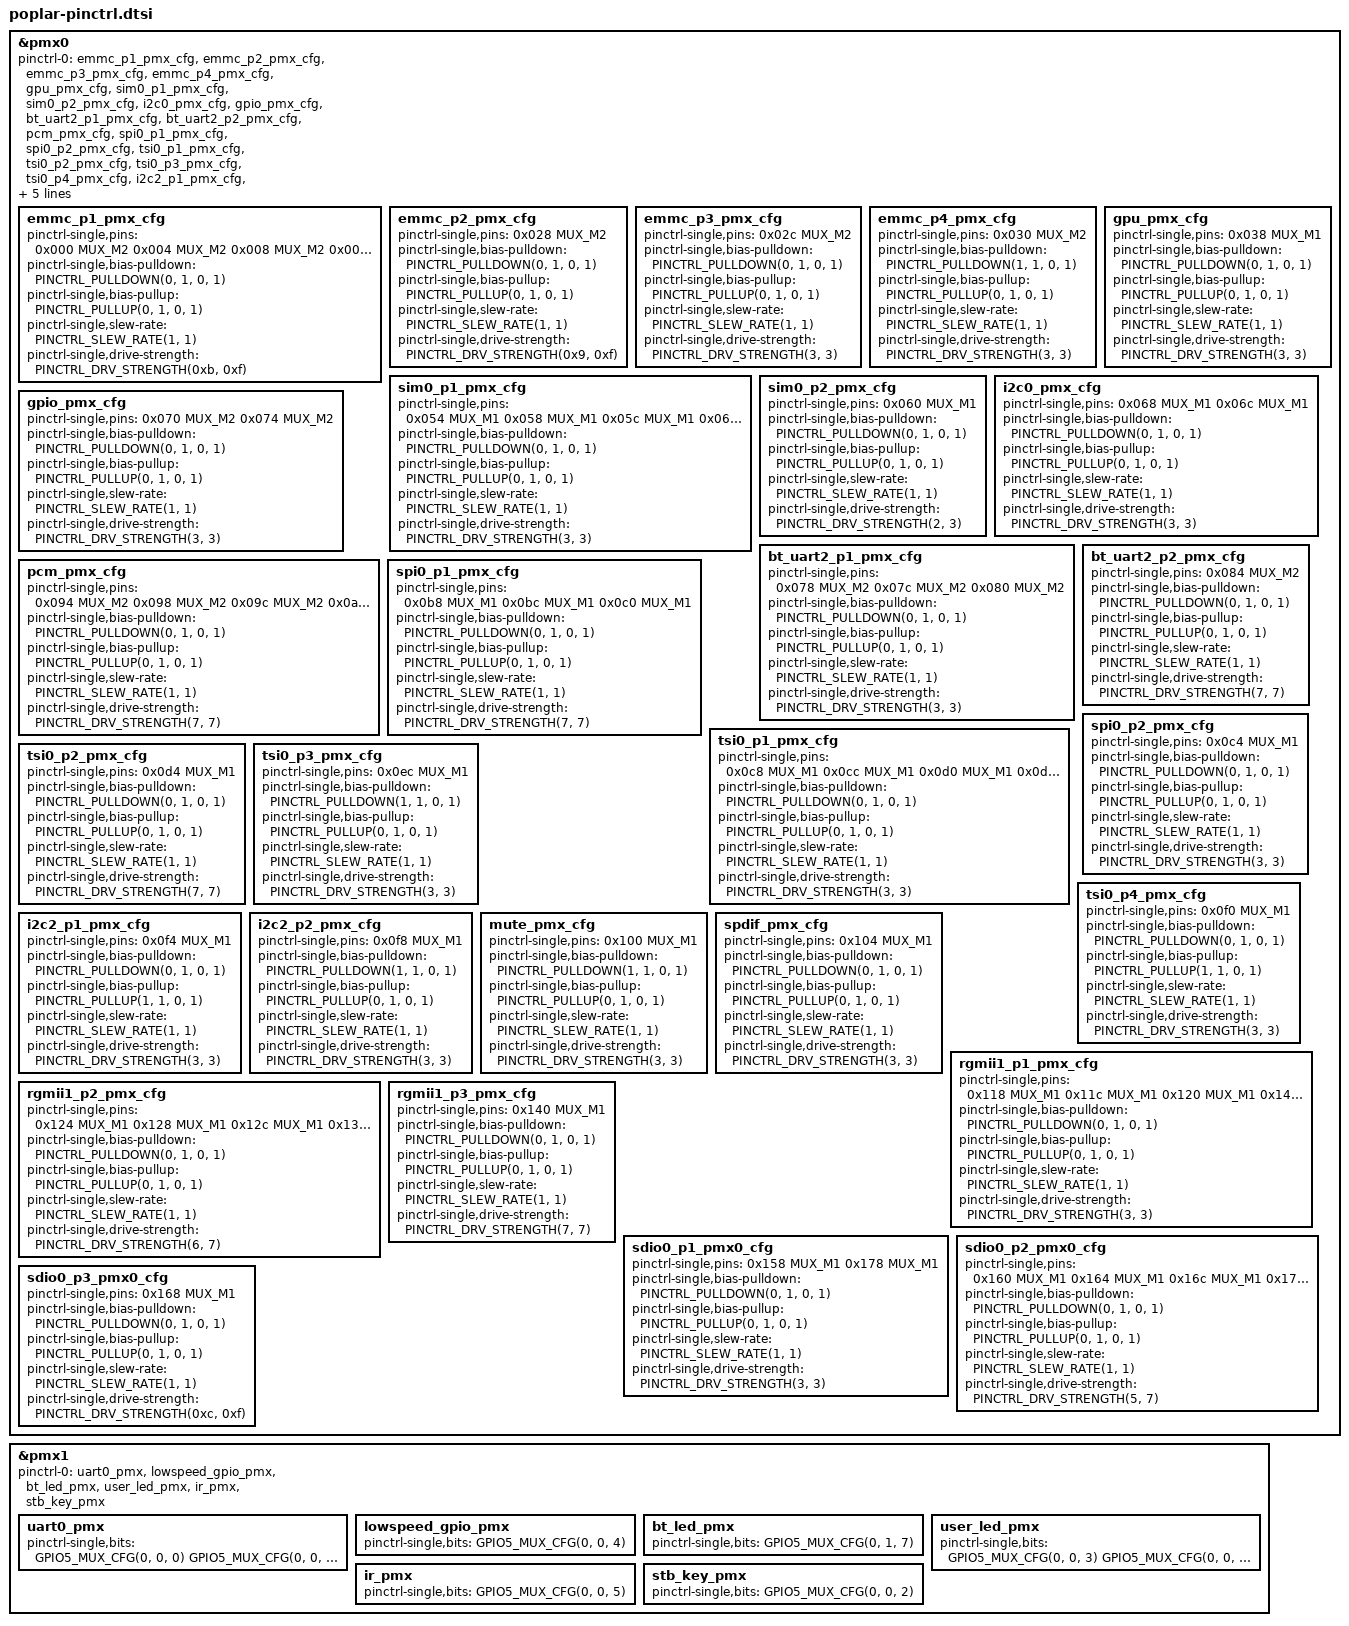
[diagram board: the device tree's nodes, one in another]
/*
 * pinctrl dts file for HiSilicon poplar board
 *
 * Copyright (c) 2016-2017 HiSilicon Technologies Co., Ltd.
 *
 * Released under the GPLv2 only.
 * SPDX-License-Identifier: GPL-2.0
 */

#include <dt-bindings/pinctrl/hisi.h>

/* value, enable bits, disable bits, mask */
#define PINCTRL_PULLDOWN(value, enable, disable, mask) \
	(value << 13) (enable << 13) (disable << 13) (mask << 13)
#define PINCTRL_PULLUP(value, enable, disable, mask) \
	(value << 12) (enable << 12) (disable << 12) (mask << 12)
#define PINCTRL_SLEW_RATE(value, mask)	  (value << 8) (mask << 8)
#define PINCTRL_DRV_STRENGTH(value, mask) (value << 4) (mask << 4)
#define GPIO5_MUX_CFG(offset, value, bit) (offset) (value << bit) (1 << bit)

&pmx0 {
	pinctrl-names = "default";
		pinctrl-0 = <
			&emmc_p1_pmx_cfg
			&emmc_p2_pmx_cfg
			&emmc_p3_pmx_cfg
			&emmc_p4_pmx_cfg
			&gpu_pmx_cfg
			&sim0_p1_pmx_cfg
			&sim0_p2_pmx_cfg
			&i2c0_pmx_cfg
			&gpio_pmx_cfg
			&bt_uart2_p1_pmx_cfg
			&bt_uart2_p2_pmx_cfg
			&pcm_pmx_cfg
			&spi0_p1_pmx_cfg
			&spi0_p2_pmx_cfg
			&tsi0_p1_pmx_cfg
			&tsi0_p2_pmx_cfg
			&tsi0_p3_pmx_cfg
			&tsi0_p4_pmx_cfg
			&i2c2_p1_pmx_cfg
			&i2c2_p2_pmx_cfg
			&mute_pmx_cfg
			&spdif_pmx_cfg
			&rgmii1_p1_pmx_cfg
			&rgmii1_p2_pmx_cfg
			&rgmii1_p3_pmx_cfg
			&sdio0_p1_pmx0_cfg
			&sdio0_p2_pmx0_cfg
			&sdio0_p3_pmx0_cfg
		>;

	emmc_p1_pmx_cfg: emmc_p1_pmx_cfg {
		pinctrl-single,pins = <
			0x000 MUX_M2
			0x004 MUX_M2
			0x008 MUX_M2
			0x00c MUX_M2
			0x010 MUX_M2
			0x014 MUX_M2
			0x018 MUX_M2
			0x01c MUX_M2
			0x024 MUX_M2
		>;
		pinctrl-single,bias-pulldown	= <
			PINCTRL_PULLDOWN(0, 1, 0, 1)
		>;
		pinctrl-single,bias-pullup	= <
			PINCTRL_PULLUP(0, 1, 0, 1)
		>;
		pinctrl-single,slew-rate	= <
			PINCTRL_SLEW_RATE(1, 1)
		>;
		pinctrl-single,drive-strength	= <
			PINCTRL_DRV_STRENGTH(0xb, 0xf)
		>;
	};

	emmc_p2_pmx_cfg: emmc_p2_pmx_cfg {
		pinctrl-single,pins = <
			0x028 MUX_M2
		>;
		pinctrl-single,bias-pulldown	= <
			PINCTRL_PULLDOWN(0, 1, 0, 1)
		>;
		pinctrl-single,bias-pullup	= <
			PINCTRL_PULLUP(0, 1, 0, 1)
		>;
		pinctrl-single,slew-rate	= <
			PINCTRL_SLEW_RATE(1, 1)
		>;
		pinctrl-single,drive-strength	= <
			PINCTRL_DRV_STRENGTH(0x9, 0xf)
		>;
	};

	emmc_p3_pmx_cfg:emmc_p3_pmx_cfg {
		pinctrl-single,pins = <
			0x02c MUX_M2
		>;
		pinctrl-single,bias-pulldown	= <
			PINCTRL_PULLDOWN(0, 1, 0, 1)
		>;
		pinctrl-single,bias-pullup	= <
			PINCTRL_PULLUP(0, 1, 0, 1)
		>;
		pinctrl-single,slew-rate	= <
			PINCTRL_SLEW_RATE(1, 1)
		>;
		pinctrl-single,drive-strength	= <
			PINCTRL_DRV_STRENGTH(3, 3)
		>;
	};

	emmc_p4_pmx_cfg:emmc_p4_pmx_cfg {
		pinctrl-single,pins = <
			0x030 MUX_M2
		>;
		pinctrl-single,bias-pulldown	= <
			PINCTRL_PULLDOWN(1, 1, 0, 1)
		>;
		pinctrl-single,bias-pullup	= <
			PINCTRL_PULLUP(0, 1, 0, 1)
		>;
		pinctrl-single,slew-rate	= <
			PINCTRL_SLEW_RATE(1, 1)
		>;
		pinctrl-single,drive-strength	= <
			PINCTRL_DRV_STRENGTH(3, 3)
		>;
	};

	gpu_pmx_cfg: gpu_pmx_cfg {
		pinctrl-single,pins = <
			0x038 MUX_M1
		>;
		pinctrl-single,bias-pulldown	= <
			PINCTRL_PULLDOWN(0, 1, 0, 1)
		>;
		pinctrl-single,bias-pullup	= <
			PINCTRL_PULLUP(0, 1, 0, 1)
		>;
		pinctrl-single,slew-rate	= <
			PINCTRL_SLEW_RATE(1, 1)
		>;
		pinctrl-single,drive-strength	= <
			PINCTRL_DRV_STRENGTH(3, 3)
		>;
	};

	sim0_p1_pmx_cfg: sim0_p1_pmx_cfg {
		pinctrl-single,pins = <
			0x054 MUX_M1
			0x058 MUX_M1
			0x05c MUX_M1
			0x064 MUX_M1
		>;
		pinctrl-single,bias-pulldown	= <
			PINCTRL_PULLDOWN(0, 1, 0, 1)
		>;
		pinctrl-single,bias-pullup	= <
			PINCTRL_PULLUP(0, 1, 0, 1)
		>;
		pinctrl-single,slew-rate	= <
			PINCTRL_SLEW_RATE(1, 1)
		>;
		pinctrl-single,drive-strength	= <
			PINCTRL_DRV_STRENGTH(3, 3)
		>;
	};

	sim0_p2_pmx_cfg: sim0_p2_pmx_cfg {
		pinctrl-single,pins = <
			0x060 MUX_M1
		>;
		pinctrl-single,bias-pulldown	= <
			PINCTRL_PULLDOWN(0, 1, 0, 1)
		>;
		pinctrl-single,bias-pullup	= <
			PINCTRL_PULLUP(0, 1, 0, 1)
		>;
		pinctrl-single,slew-rate	= <
			PINCTRL_SLEW_RATE(1, 1)
		>;
		pinctrl-single,drive-strength	= <
			PINCTRL_DRV_STRENGTH(2, 3)
		>;
	};

	i2c0_pmx_cfg: i2c0_pmx_cfg {
		pinctrl-single,pins = <
			0x068 MUX_M1
			0x06c MUX_M1
		>;
		pinctrl-single,bias-pulldown	= <
			PINCTRL_PULLDOWN(0, 1, 0, 1)
		>;
		pinctrl-single,bias-pullup	= <
			PINCTRL_PULLUP(0, 1, 0, 1)
		>;
		pinctrl-single,slew-rate	= <
			PINCTRL_SLEW_RATE(1, 1)
		>;
		pinctrl-single,drive-strength	= <
			PINCTRL_DRV_STRENGTH(3, 3)
		>;
	};

	gpio_pmx_cfg: gpio_pmx_cfg {
		pinctrl-single,pins = <
			0x070 MUX_M2
			0x074 MUX_M2
		>;
		pinctrl-single,bias-pulldown	= <
			PINCTRL_PULLDOWN(0, 1, 0, 1)
		>;
		pinctrl-single,bias-pullup	= <
			PINCTRL_PULLUP(0, 1, 0, 1)
		>;
		pinctrl-single,slew-rate	= <
			PINCTRL_SLEW_RATE(1, 1)
		>;
		pinctrl-single,drive-strength	= <
			PINCTRL_DRV_STRENGTH(3, 3)
		>;
	};

	bt_uart2_p1_pmx_cfg: bt_uart2_p1_pmx_cfg {
		pinctrl-single,pins = <
			0x078 MUX_M2
			0x07c MUX_M2
			0x080 MUX_M2
		>;
		pinctrl-single,bias-pulldown	= <
			PINCTRL_PULLDOWN(0, 1, 0, 1)
		>;
		pinctrl-single,bias-pullup	= <
			PINCTRL_PULLUP(0, 1, 0, 1)
		>;
		pinctrl-single,slew-rate	= <
			PINCTRL_SLEW_RATE(1, 1)
		>;
		pinctrl-single,drive-strength	= <
			PINCTRL_DRV_STRENGTH(3, 3)
		>;
	};

	bt_uart2_p2_pmx_cfg: bt_uart2_p2_pmx_cfg {
		pinctrl-single,pins = <
			0x084 MUX_M2
		>;
		pinctrl-single,bias-pulldown	= <
			PINCTRL_PULLDOWN(0, 1, 0, 1)
		>;
		pinctrl-single,bias-pullup	= <
			PINCTRL_PULLUP(0, 1, 0, 1)
		>;
		pinctrl-single,slew-rate	= <
			PINCTRL_SLEW_RATE(1, 1)
		>;
		pinctrl-single,drive-strength	= <
			PINCTRL_DRV_STRENGTH(7, 7)
		>;
	};

	pcm_pmx_cfg: pcm_pmx_cfg {
		pinctrl-single,pins = <
			0x094 MUX_M2
			0x098 MUX_M2
			0x09c MUX_M2
			0x0a0 MUX_M2
		>;
		pinctrl-single,bias-pulldown	= <
			PINCTRL_PULLDOWN(0, 1, 0, 1)
		>;
		pinctrl-single,bias-pullup	= <
			PINCTRL_PULLUP(0, 1, 0, 1)
		>;
		pinctrl-single,slew-rate	= <
			PINCTRL_SLEW_RATE(1, 1)
		>;
		pinctrl-single,drive-strength	= <
			PINCTRL_DRV_STRENGTH(7, 7)
		>;
	};

	spi0_p1_pmx_cfg: spi0_p1_pmx_cfg {
		pinctrl-single,pins = <
			0x0b8 MUX_M1
			0x0bc MUX_M1
			0x0c0 MUX_M1
		>;
		pinctrl-single,bias-pulldown	= <
			PINCTRL_PULLDOWN(0, 1, 0, 1)
		>;
		pinctrl-single,bias-pullup	= <
			PINCTRL_PULLUP(0, 1, 0, 1)
		>;
		pinctrl-single,slew-rate	= <
			PINCTRL_SLEW_RATE(1, 1)
		>;
		pinctrl-single,drive-strength	= <
			PINCTRL_DRV_STRENGTH(7, 7)
		>;
	};

	spi0_p2_pmx_cfg: spi0_p2_pmx_cfg {
		pinctrl-single,pins = <
			0x0c4 MUX_M1
		>;
		pinctrl-single,bias-pulldown	= <
			PINCTRL_PULLDOWN(0, 1, 0, 1)
		>;
		pinctrl-single,bias-pullup	= <
			PINCTRL_PULLUP(0, 1, 0, 1)
		>;
		pinctrl-single,slew-rate	= <
			PINCTRL_SLEW_RATE(1, 1)
		>;
		pinctrl-single,drive-strength	= <
			PINCTRL_DRV_STRENGTH(3, 3)
		>;
	};

	tsi0_p1_pmx_cfg: tsi0_p1_pmx_cfg {
		pinctrl-single,pins = <
			0x0c8 MUX_M1
			0x0cc MUX_M1
			0x0d0 MUX_M1
			0x0d8 MUX_M1
			0x0dc MUX_M1
			0x0e0 MUX_M1
			0x0e4 MUX_M1
			0x0e8 MUX_M1
		>;
		pinctrl-single,bias-pulldown	= <
			PINCTRL_PULLDOWN(0, 1, 0, 1)
		>;
		pinctrl-single,bias-pullup	= <
			PINCTRL_PULLUP(0, 1, 0, 1)
		>;
		pinctrl-single,slew-rate	= <
			PINCTRL_SLEW_RATE(1, 1)
		>;
		pinctrl-single,drive-strength	= <
			PINCTRL_DRV_STRENGTH(3, 3)
		>;
	};

	tsi0_p2_pmx_cfg: tsi0_p2_pmx_cfg {
		pinctrl-single,pins = <
			0x0d4 MUX_M1
		>;
		pinctrl-single,bias-pulldown	= <
			PINCTRL_PULLDOWN(0, 1, 0, 1)
		>;
		pinctrl-single,bias-pullup	= <
			PINCTRL_PULLUP(0, 1, 0, 1)
		>;
		pinctrl-single,slew-rate	= <
			PINCTRL_SLEW_RATE(1, 1)
		>;
		pinctrl-single,drive-strength	= <
			PINCTRL_DRV_STRENGTH(7, 7)
		>;
	};

	tsi0_p3_pmx_cfg: tsi0_p3_pmx_cfg {
		pinctrl-single,pins = <
			0x0ec MUX_M1
		>;
		pinctrl-single,bias-pulldown	= <
			PINCTRL_PULLDOWN(1, 1, 0, 1)
		>;
		pinctrl-single,bias-pullup	= <
			PINCTRL_PULLUP(0, 1, 0, 1)
		>;
		pinctrl-single,slew-rate	= <
			PINCTRL_SLEW_RATE(1, 1)
		>;
		pinctrl-single,drive-strength	= <
			PINCTRL_DRV_STRENGTH(3, 3)
		>;
	};

	tsi0_p4_pmx_cfg: tsi0_p4_pmx_cfg  {
		pinctrl-single,pins = <
			0x0f0 MUX_M1
		>;
		pinctrl-single,bias-pulldown	= <
			PINCTRL_PULLDOWN(0, 1, 0, 1)
		>;
		pinctrl-single,bias-pullup	= <
			PINCTRL_PULLUP(1, 1, 0, 1)
		>;
		pinctrl-single,slew-rate	= <
			PINCTRL_SLEW_RATE(1, 1)
		>;
		pinctrl-single,drive-strength	= <
			PINCTRL_DRV_STRENGTH(3, 3)
		>;
	};

	i2c2_p1_pmx_cfg: i2c2_p1_pmx_cfg {
		pinctrl-single,pins = <
			0x0f4 MUX_M1
		>;
		pinctrl-single,bias-pulldown   = <
			PINCTRL_PULLDOWN(0, 1, 0, 1)
		>;
		pinctrl-single,bias-pullup  = <
			PINCTRL_PULLUP(1, 1, 0, 1)
		>;
		pinctrl-single,slew-rate    = <
			PINCTRL_SLEW_RATE(1, 1)
		>;
		pinctrl-single,drive-strength   = <
			PINCTRL_DRV_STRENGTH(3, 3)
		>;
	};

	i2c2_p2_pmx_cfg: i2c2_p2_pmx_cfg {
		pinctrl-single,pins = <
			0x0f8 MUX_M1
		>;
		pinctrl-single,bias-pulldown   = <
			PINCTRL_PULLDOWN(1, 1, 0, 1)
		>;
		pinctrl-single,bias-pullup  = <
			PINCTRL_PULLUP(0, 1, 0, 1)
		>;
		pinctrl-single,slew-rate    = <
			PINCTRL_SLEW_RATE(1, 1)
		>;
		pinctrl-single,drive-strength   = <
			PINCTRL_DRV_STRENGTH(3, 3)
		>;
	};

	mute_pmx_cfg: mute_pmx_cfg {
		pinctrl-single,pins = <
			0x100 MUX_M1
		>;
		pinctrl-single,bias-pulldown   = <
			PINCTRL_PULLDOWN(1, 1, 0, 1)
		>;
		pinctrl-single,bias-pullup  = <
			PINCTRL_PULLUP(0, 1, 0, 1)
		>;
		pinctrl-single,slew-rate    = <
			PINCTRL_SLEW_RATE(1, 1)
		>;
		pinctrl-single,drive-strength   = <
			PINCTRL_DRV_STRENGTH(3, 3)
		>;
	};

	spdif_pmx_cfg: spdif_pmx_cfg {
		pinctrl-single,pins = <
			0x104 MUX_M1
		>;
		pinctrl-single,bias-pulldown   = <
			PINCTRL_PULLDOWN(0, 1, 0, 1)
		>;
		pinctrl-single,bias-pullup  = <
			PINCTRL_PULLUP(0, 1, 0, 1)
		>;
		pinctrl-single,slew-rate    = <
			PINCTRL_SLEW_RATE(1, 1)
		>;
		pinctrl-single,drive-strength   = <
			PINCTRL_DRV_STRENGTH(3, 3)
		>;
	};

	rgmii1_p1_pmx_cfg: rgmii1_p1_pmx_cfg {
		pinctrl-single,pins = <
			0x118 MUX_M1
			0x11c MUX_M1
			0x120 MUX_M1
			0x144 MUX_M1
			0x148 MUX_M1
			0x14c MUX_M1
			0x150 MUX_M1
			0x154 MUX_M1
		>;
		pinctrl-single,bias-pulldown    = <
			PINCTRL_PULLDOWN(0, 1, 0, 1)
		>;
		pinctrl-single,bias-pullup  = <
			PINCTRL_PULLUP(0, 1, 0, 1)
		>;
		pinctrl-single,slew-rate    = <
			PINCTRL_SLEW_RATE(1, 1)
		>;
		pinctrl-single,drive-strength   = <
			PINCTRL_DRV_STRENGTH(3, 3)
		>;
	};

	rgmii1_p2_pmx_cfg: rgmii1_p2_pmx_cfg {
		pinctrl-single,pins = <
			0x124 MUX_M1
			0x128 MUX_M1
			0x12c MUX_M1
			0x130 MUX_M1
			0x134 MUX_M1
			0x13c MUX_M1
		>;
		pinctrl-single,bias-pulldown    = <
			PINCTRL_PULLDOWN(0, 1, 0, 1)
		>;
		pinctrl-single,bias-pullup   = <
			PINCTRL_PULLUP(0, 1, 0, 1)
		>;
		pinctrl-single,slew-rate    = <
			PINCTRL_SLEW_RATE(1, 1)
		>;
		pinctrl-single,drive-strength   = <
			PINCTRL_DRV_STRENGTH(6, 7)
		>;
	};

	rgmii1_p3_pmx_cfg: rgmii1_p3_pmx_cfg {
		pinctrl-single,pins = <
			0x140 MUX_M1
		>;
		pinctrl-single,bias-pulldown    = <
			PINCTRL_PULLDOWN(0, 1, 0, 1)
		>;
		pinctrl-single,bias-pullup   = <
			PINCTRL_PULLUP(0, 1, 0, 1)
		>;
		pinctrl-single,slew-rate    = <
			PINCTRL_SLEW_RATE(1, 1)
		>;
		pinctrl-single,drive-strength   = <
			PINCTRL_DRV_STRENGTH(7, 7)
		>;
	};

	sdio0_p1_pmx0_cfg: sdio0_p1_pmx0_cfg {
		pinctrl-single,pins = <
			0x158 MUX_M1
			0x178 MUX_M1
		>;
		pinctrl-single,bias-pulldown    = <
			PINCTRL_PULLDOWN(0, 1, 0, 1)
		>;
		pinctrl-single,bias-pullup   = <
			PINCTRL_PULLUP(0, 1, 0, 1)
		>;
		pinctrl-single,slew-rate    = <
			PINCTRL_SLEW_RATE(1, 1)
		>;
		pinctrl-single,drive-strength   = <
			PINCTRL_DRV_STRENGTH(3, 3)
		>;
	};

	sdio0_p2_pmx0_cfg: sdio0_p2_pmx0_cfg {
		pinctrl-single,pins = <
			0x160 MUX_M1
			0x164 MUX_M1
			0x16c MUX_M1
			0x170 MUX_M1
			0x174 MUX_M1
		>;
		pinctrl-single,bias-pulldown    = <
			PINCTRL_PULLDOWN(0, 1, 0, 1)
		>;
		pinctrl-single,bias-pullup   = <
			PINCTRL_PULLUP(0, 1, 0, 1)
		>;
		pinctrl-single,slew-rate    = <
			PINCTRL_SLEW_RATE(1, 1)
		>;
		pinctrl-single,drive-strength   = <
			PINCTRL_DRV_STRENGTH(5, 7)
		>;
	};

	sdio0_p3_pmx0_cfg: sdio0_p3_pmx0_cfg {
		pinctrl-single,pins = <
			0x168 MUX_M1
		>;
		pinctrl-single,bias-pulldown    = <
			PINCTRL_PULLDOWN(0, 1, 0, 1)
		>;
		pinctrl-single,bias-pullup   = <
			PINCTRL_PULLUP(0, 1, 0, 1)
		>;
		pinctrl-single,slew-rate    = <
			PINCTRL_SLEW_RATE(1, 1)
		>;
		pinctrl-single,drive-strength   = <
			PINCTRL_DRV_STRENGTH(0xc, 0xf)
		>;
	};
};

&pmx1{
	pinctrl-names = "default";
	pinctrl-0 = <
		&uart0_pmx
		&lowspeed_gpio_pmx
		&bt_led_pmx
		&user_led_pmx
		&ir_pmx
		&stb_key_pmx
	>;

	uart0_pmx: uart0_pmx {
		pinctrl-single,bits = <
			GPIO5_MUX_CFG(0, 0, 0)
			GPIO5_MUX_CFG(0, 0, 1)
		>;
	};

	lowspeed_gpio_pmx: lowspeed_gpio_pmx {
		pinctrl-single,bits = <
			GPIO5_MUX_CFG(0, 0, 4)
		>;
	};

	bt_led_pmx: bt_led_pmx {
		pinctrl-single,bits = <
			GPIO5_MUX_CFG(0, 1, 7)
		>;
	};

	user_led_pmx: user_led_pmx {
		pinctrl-single,bits = <
			GPIO5_MUX_CFG(0, 0, 3)
			GPIO5_MUX_CFG(0, 0, 6)
		>;
	};

	ir_pmx: ir_pmx {
		pinctrl-single,bits = <
			GPIO5_MUX_CFG(0, 0, 5)
		>;
	};

	stb_key_pmx:stb_key_pmx {
		pinctrl-single,bits = <
			GPIO5_MUX_CFG(0, 0, 2)
		>;
	};
};
